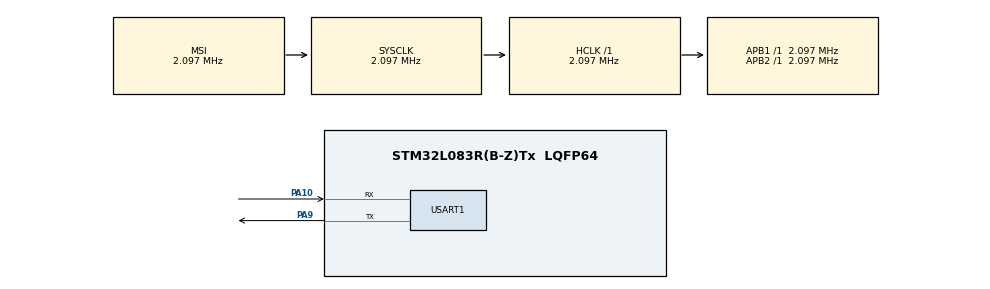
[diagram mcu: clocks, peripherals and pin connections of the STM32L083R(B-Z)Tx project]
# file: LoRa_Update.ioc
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Mcu.Family=STM32L0
Mcu.Name=STM32L083R(B-Z)Tx
Mcu.Package=LQFP64
PA10.Mode=Asynchronous
PA10.Signal=USART1_RX
PA9.Mode=Asynchronous
PA9.Signal=USART1_TX
ProjectManager.HeapSize=0x200
ProjectManager.StackSize=0x400
ProjectManager.TargetToolchain=MDK-ARM V5
RCC.AHBFreq_Value=2097000
RCC.APB1Freq_Value=2097000
RCC.APB1TimFreq_Value=2097000
RCC.APB2Freq_Value=2097000
RCC.APB2TimFreq_Value=2097000
RCC.HSE_VALUE=8000000
RCC.HSI16_VALUE=16000000
RCC.HSI48_VALUE=48000000
RCC.HSI_VALUE=16000000
RCC.LSE_VALUE=32768
RCC.MSI_VALUE=2097000
RCC.SYSCLKFreq_VALUE=2097000
RCC.VCOOutputFreq_Value=48000000
USART1.VirtualMode-Asynchronous=VM_ASYNC
board=custom

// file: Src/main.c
/* USER CODE BEGIN Header */
/**
  ******************************************************************************
  * @file           : main.c
  * @brief          : Main program body
  ******************************************************************************
  ** This notice applies to any and all portions of this file
  * that are not between comment pairs USER CODE BEGIN and
  * USER CODE END. Other portions of this file, whether
  * inserted by the user or by software development tools
  * are owned by their respective copyright owners.
  *
  * COPYRIGHT(c) 2019 STMicroelectronics
  *
  * Redistribution and use in source and binary forms, with or without modification,
  * are permitted provided that the following conditions are met:
  *   1. Redistributions of source code must retain the above copyright notice,
  *      this list of conditions and the following disclaimer.
  *   2. Redistributions in binary form must reproduce the above copyright notice,
  *      this list of conditions and the following disclaimer in the documentation
  *      and/or other materials provided with the distribution.
  *   3. Neither the name of STMicroelectronics nor the names of its contributors
  *      may be used to endorse or promote products derived from this software
  *      without specific prior written permission.
  *
  * THIS SOFTWARE IS PROVIDED BY THE COPYRIGHT HOLDERS AND CONTRIBUTORS "AS IS"
  * AND ANY EXPRESS OR IMPLIED WARRANTIES, INCLUDING, BUT NOT LIMITED TO, THE
  * IMPLIED WARRANTIES OF MERCHANTABILITY AND FITNESS FOR A PARTICULAR PURPOSE ARE
  * DISCLAIMED. IN NO EVENT SHALL THE COPYRIGHT HOLDER OR CONTRIBUTORS BE LIABLE
  * FOR ANY DIRECT, INDIRECT, INCIDENTAL, SPECIAL, EXEMPLARY, OR CONSEQUENTIAL
  * DAMAGES (INCLUDING, BUT NOT LIMITED TO, PROCUREMENT OF SUBSTITUTE GOODS OR
  * SERVICES; LOSS OF USE, DATA, OR PROFITS; OR BUSINESS INTERRUPTION) HOWEVER
  * CAUSED AND ON ANY THEORY OF LIABILITY, WHETHER IN CONTRACT, STRICT LIABILITY,
  * OR TORT (INCLUDING NEGLIGENCE OR OTHERWISE) ARISING IN ANY WAY OUT OF THE USE
  * OF THIS SOFTWARE, EVEN IF ADVISED OF THE POSSIBILITY OF SUCH DAMAGE.
  *
  ******************************************************************************
  */
/* USER CODE END Header */

#include "main.h"
#include "update.h"
#include "common.h"

UART_HandleTypeDef huart1;

void SystemClock_Config(void);
static void MX_GPIO_Init(void);
static void MX_USART1_UART_Init(void);

int main(void)
{
  /* USER CODE BEGIN 1 */
	//uint8_t key = 0;
  /* USER CODE END 1 */

  /* MCU Configuration--------------------------------------------------------*/

  /* Reset of all peripherals, Initializes the Flash interface and the Systick. */
  HAL_Init();

  /* Configure the system clock */
  SystemClock_Config();

  /* Initialize all configured peripherals */
  MX_GPIO_Init();
  MX_USART1_UART_Init();
  /* USER CODE BEGIN 2 */

	update();

  /* USER CODE END 2 */

  /* Infinite loop */
  while (1)
  {

  }
}

void SystemClock_Config(void)
{
  RCC_OscInitTypeDef RCC_OscInitStruct = {0};
  RCC_ClkInitTypeDef RCC_ClkInitStruct = {0};
  RCC_PeriphCLKInitTypeDef PeriphClkInit = {0};

  /**Configure the main internal regulator output voltage
  */
  __HAL_PWR_VOLTAGESCALING_CONFIG(PWR_REGULATOR_VOLTAGE_SCALE1);
  /**Initializes the CPU, AHB and APB busses clocks
  */
  RCC_OscInitStruct.OscillatorType = RCC_OSCILLATORTYPE_MSI;
  RCC_OscInitStruct.MSIState = RCC_MSI_ON;
  RCC_OscInitStruct.MSICalibrationValue = 0;
  RCC_OscInitStruct.MSIClockRange = RCC_MSIRANGE_5;
  RCC_OscInitStruct.PLL.PLLState = RCC_PLL_NONE;
  if (HAL_RCC_OscConfig(&RCC_OscInitStruct) != HAL_OK)
  {
    Error_Handler();
  }
  /**Initializes the CPU, AHB and APB busses clocks
  */
  RCC_ClkInitStruct.ClockType = RCC_CLOCKTYPE_HCLK|RCC_CLOCKTYPE_SYSCLK
                              |RCC_CLOCKTYPE_PCLK1|RCC_CLOCKTYPE_PCLK2;
  RCC_ClkInitStruct.SYSCLKSource = RCC_SYSCLKSOURCE_MSI;
  RCC_ClkInitStruct.AHBCLKDivider = RCC_SYSCLK_DIV1;
  RCC_ClkInitStruct.APB1CLKDivider = RCC_HCLK_DIV1;
  RCC_ClkInitStruct.APB2CLKDivider = RCC_HCLK_DIV1;

  if (HAL_RCC_ClockConfig(&RCC_ClkInitStruct, FLASH_LATENCY_0) != HAL_OK)
  {
    Error_Handler();
  }
  PeriphClkInit.PeriphClockSelection = RCC_PERIPHCLK_USART1;
  PeriphClkInit.Usart1ClockSelection = RCC_USART1CLKSOURCE_PCLK2;
  if (HAL_RCCEx_PeriphCLKConfig(&PeriphClkInit) != HAL_OK)
  {
    Error_Handler();
  }
}

static void MX_USART1_UART_Init(void)
{

  huart1.Instance = USART1;
  huart1.Init.BaudRate = 115200;
  huart1.Init.WordLength = UART_WORDLENGTH_8B;
  huart1.Init.StopBits = UART_STOPBITS_1;
  huart1.Init.Parity = UART_PARITY_NONE;
  huart1.Init.Mode = UART_MODE_TX_RX;
  huart1.Init.HwFlowCtl = UART_HWCONTROL_NONE;
  huart1.Init.OverSampling = UART_OVERSAMPLING_16;
  huart1.Init.OneBitSampling = UART_ONE_BIT_SAMPLE_DISABLE;
  huart1.AdvancedInit.AdvFeatureInit = UART_ADVFEATURE_NO_INIT;
  if (HAL_UART_Init(&huart1) != HAL_OK)
  {
    Error_Handler();
  }

}

static void MX_GPIO_Init(void)
{

  /* GPIO Ports Clock Enable */
  __HAL_RCC_GPIOA_CLK_ENABLE();

}

void Error_Handler(void)
{
}

/************************ (C) COPYRIGHT STMicroelectronics *****END OF FILE****/
